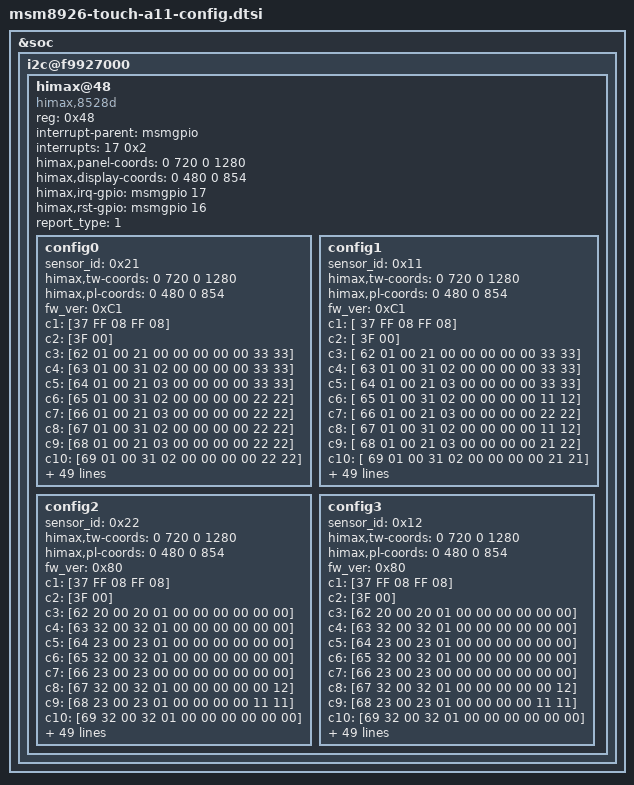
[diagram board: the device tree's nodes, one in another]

/* Copyright (c) 2013, The Linux Foundation. All rights reserved.
 *
 * This program is free software; you can redistribute it and/or modify
 * it under the terms of the GNU General Public License version 2 and
 * only version 2 as published by the Free Software Foundation.
 *
 * This program is distributed in the hope that it will be useful,
 * but WITHOUT ANY WARRANTY; without even the implied warranty of
 * MERCHANTABILITY or FITNESS FOR A PARTICULAR PURPOSE.  See the
 * GNU General Public License for more details.
 */

&soc {
	i2c@f9927000 { /* BLSP1 QUP5 */
		himax@48 {
		compatible               	= "himax,8528d";
		reg                      		= <0x48>;
		interrupt-parent         	= <&msmgpio>;
		interrupts               	= <17 0x2>;
		himax,panel-coords   	= <0 720 0 1280>;
		himax,display-coords 	= <0 480 0 854>;
		himax,irq-gpio       	= <&msmgpio 17 0x00>;
		himax,rst-gpio       	= <&msmgpio 16 0x00>;
		report_type              	= <1>;

	config0 {	//A3 Henghao edge lamination 2nd
			sensor_id   	= <0x21>;
			himax,tw-coords   	= <0 720 0 1280>;
			himax,pl-coords 	= <0 480 0 854>;
			fw_ver     	= <0xC1>;
			c1 =[37 FF 08 FF 08];
			c2 =[3F 00];
			c3 =[62 01 00 21 00 00 00 00 00 33 33];
			c4 =[63 01 00 31 02 00 00 00 00 33 33];
			c5 =[64 01 00 21 03 00 00 00 00 33 33];
			c6 =[65 01 00 31 02 00 00 00 00 22 22];
			c7 =[66 01 00 21 03 00 00 00 00 22 22];
			c8 =[67 01 00 31 02 00 00 00 00 22 22];
			c9 =[68 01 00 21 03 00 00 00 00 22 22];
			c10 =[69 01 00 31 02 00 00 00 00 22 22];
			c11 =[6A 01 00 21 00 00 00 00 00 02 00];
			c12 =[6B 01 00 01 02 00 00 00 00 00 00];
			c13 =[6C 01 00 21 00 00 00 00 00 00 00];
			c14 =[6D 01 00 01 02 00 00 00 00 00 00];
			c15 =[6E 00 00 20 00 00 00 00 00 00 00];
			c16 =[6F 00 00 00 02 00 00 00 00 00 00];
			c17 =[70 00 00 00 00 00 00 00 00 00 00];
			c18 =[7B 03];
			c19 =[7C 00 D8 0C];
			c20 =[7F 00 04 0A 0A 04 00 00 00];
			c21 =[A4 94 62 94 86];
			c22 =[B4 06 01 02 02 02 03 0F 03 0F 03
			          0F 03 0F 08];
			c23 =[B9 01 36];
			c24 =[BA 00];
			c25 =[BB 00];
			c26 =[BC 00 00 00 00];
			c27 =[BD 04 0C];
			c28 =[C2 10 00 00 00 00 00 00 00];
			c29 =[C5 0A 1B 00 10 1A 1E 0B 1A 08 16];
			c30 =[C6 17 10 1E];
			c31 =[C9 00 00 00 26 24 22 20 1C 1A 18
			          16 14 12 10 25 23 21 1D 1B 19
			          17 15 13 11 00 00 00 00 00 00
			          00 00 00 00 00 00 00 00 00 00
			          00 00 00 00 00 00 00 00 00 00
			          00 00 00 00 00 00 00 00 00 00
			          00 00 00 00];
			c32 =[CB 01 F5 FF FF 01 00 05 00 5F 00
			          00 00];
			c33 =[D0 06 01];
			c34 =[D3 06 01];
			c35 =[D5 29 00 00 00 00 00 00 00 00 00
			          00 00 00 00 00 00];
			c36 =[40 0D 5A
			          5F 00 F0 10 00 00
			          38 0C 0B 12 0A 0C 0A 0C 0C 0C
			          24 20 40 40 3C 00 00 00 00 05
			          10 20];
			c37 =[40 94 08 80 83 84 00
			          48 24 0F 14 83 3C 00 00
			          11 00 41 42
			          0F 3F 00 12 00 00
			          10 02 3C 64 00 00];
			c38 =[40 18 3F 3F 04 14 00 00 00
			          04 06 24 06 06 00 00 00];
			c39 =[40 30 58 05 00 00 D8 0C 00 00 02
			          03 80 00 00 00 00
			          10 02 80 00 00 00 00 0C];
			c40 =[40 00 00 00 00 00 00 00 00
			          A0 82 2D 01
			          0C 15 A0 13
			          00 00 02 D0 05 01];
			c41 =[40 03 E2 08 01 47 3F 08 00 61 01
			          6A 41 28 0C
			          05 EF 0C 3D 4C 95 00 00 E4 03
			          56 45 8F 00];
			c42 =[40 00 00 00 00 00 00 00 00];
			c43_1 =[40 04 20 FF FF 08 1F 12 FF 03 1E
			             11 FF 09 1D 10 FF 02 1C 0F FF
			             07 1B 0E FF 05 1A 0D FF 06 19
			             0C];
			c43_2 =[40 FF 0A 18 FF FF 01 17 FF FF
			             0B 16 FF FF 00 15 FF FF FF 14
			             FF FF FF 13 FF FF FF FF FF FF];
			c44_1 =[40 A3 00 20 00 13 1E 32 00 00 00
			             00 00 00 00 00 00 00 00 00 00
			             00 00 00 00 00 00 00 00 00 00
			             56];
			c44_2 =[40 02 12 02 00 04];
			c45   =[40 00 00];
			};

	config1 {	//Henghao edge lamination, with connecting line
			sensor_id   	= <0x11>;
			himax,tw-coords   	= <0 720 0 1280>;
			himax,pl-coords 	= <0 480 0 854>;
			fw_ver     	= <0xC1>;

			c1 =  [ 37 FF 08 FF 08];
			c2 =  [ 3F 00];
			c3 =  [ 62 01 00 21 00 00 00 00 00 33 33];
			c4 =  [ 63 01 00 31 02 00 00 00 00 33 33];
			c5 =  [ 64 01 00 21 03 00 00 00 00 33 33];
			c6 =  [ 65 01 00 31 02 00 00 00 00 11 12];
			c7 =  [ 66 01 00 21 03 00 00 00 00 22 22];
			c8 =  [ 67 01 00 31 02 00 00 00 00 11 12];
			c9 =  [ 68 01 00 21 03 00 00 00 00 21 22];
			c10 = [ 69 01 00 31 02 00 00 00 00 21 21];
			c11 = [ 6A 01 00 21 00 00 00 00 00 01 00];
			c12 = [ 6B 01 00 01 02 00 00 00 00 00 00];
			c13 = [ 6C 01 00 21 00 00 00 00 00 00 00];
			c14 = [ 6D 01 00 01 02 00 00 00 00 00 00];
			c15 = [ 6E 00 00 20 00 00 00 00 00 00 00];
			c16 = [ 6F 00 00 00 02 00 00 00 00 00 00];
			c17 = [ 70 00 00 00 00 00 00 00 00 00 00];
			c18 = [ 7B 03];
			c19 = [ 7C 00 D8 0C];
			c20 = [ 7F 00 04 0A 0A 04 00 00 00];
			c21 = [ A4 94 62 94 86];
			c22 = [ B4 06 01 02 02 02 03 0F 03 0F 03
			               0F 03 0F 08];
			c23 = [ B9 01 36];
			c24 = [ BA 00];
			c25 = [ BB 00];
			c26 = [ BC 00 00 00 00];
			c27 = [ BD 04 0C];
			c28 = [ C2 10 00 00 00 00 00 00 00];
			c29 = [ C5 0A 1F 00 10 1A 1E 0B 1F 08 16];
			c30 = [ C6 17 10 1E];
			c31 = [ C9 00 00 00 26 24 22 20 1C 1A 18
			               16 14 12 10 25 23 21 1D 1B 19
			               17 15 13 11 00 00 00 00 00 00
			               00 00 00 00 00 00 00 00 00 00
			               00 00 00 00 00 00 00 00 00 00
			               00 00 00 00 00 00 00 00 00 00
			               00 00 00 00];
			c32 = [ CB 01 F5 FF FF 01 00 05 00 5F 00
			               00 00];
			c33 = [ D0 06 01];
			c34 = [ D3 06 01];
			c35 = [ D5 29 00 00 00 00 00 00 00 00 00
			               00 00 00 00 00 00];
			c36 = [ 40 0D 5A
			               5F 00 F0 10 00 00
			               38 0C 0B 12 0A 0C 0A 0C 0C 0C
			               24 20 40 40 3C 00 00 00 00 05
			               10 20];
			c37 = [ 40 94 08 80 83 84 00
			               48 24 0F 14 83 3C 00 00
			               11 00 41 42
			               0F 3F 00 12 00 00
			               10 02 3C 64 00 00];
			c38 = [ 40 18 3F 3F 04 14 00 00 00
			               04 06 24 06 06 00 00 00];
			c39 = [ 40 30 58 05 00 00 D8 0C 00 00 02
			               03 80 00 00 00 00
			               10 02 80 00 00 00 00 0C];
			c40 = [ 40 00 00 00 00 00 00 00 00
			               A0 82 2D 01
			               0C 15 A0 13
			               00 00 02 D0 05 01];
			c41 = [ 40 03 E2 08 01 47 3F 08 00 61 01
			               6A 41 28 0C
			               05 EF 0C 3D 4C 95 00 00 E4 03
			               56 45 8F 00];
			c42 = [ 40 00 00 00 00 00 00 00 00];

			c43_1 = [ 40 04 20 FF FF 08 1F 12 FF 03 1E
			                 11 FF 09 1D 10 FF 02 1C 0F FF
			                 07 1B 0E FF 05 1A 0D FF 06 19
			                 0C];
			c43_2 = [ 40 FF 0A 18 FF FF 01 17 FF FF
			                 0B 16 FF FF 00 15 FF FF FF 14
			                 FF FF FF 13 FF FF FF FF FF FF];
			c44_1 = [ 40 A3 00 20 00 13 1E 32 00 00 00
			                 00 00 00 00 00 00 00 00 00 00
			                 00 00 00 00 00 00 00 00 00 00
			                 56];
			c44_2 = [ 40       02 12 02 00 04];
			c45   = [ 40 00 00];
			};

	config2 {//YFO one layer TW for A11#CHL&AIO, version begins from 0x80
			sensor_id   	= <0x22>;
			himax,tw-coords   	= <0 720 0 1280>;
			himax,pl-coords 	= <0 480 0 854>;
			fw_ver     	= <0x80>;
			c1 =[37 FF 08 FF 08];
			c2 =[3F 00];
			c3 =[62 20 00 20 01 00 00 00 00 00 00];
			c4 =[63 32 00 32 01 00 00 00 00 00 00];
			c5 =[64 23 00 23 01 00 00 00 00 00 00];
			c6 =[65 32 00 32 01 00 00 00 00 00 00];
			c7 =[66 23 00 23 00 00 00 00 00 00 00];
			c8 =[67 32 00 32 01 00 00 00 00 00 12];
			c9 =[68 23 00 23 01 00 00 00 00 11 11];
			c10 =[69 32 00 32 01 00 00 00 00 00 00];
			c11 =[6A 23 00 23 00 00 00 00 00 00 00];
			c12 =[6B 02 00 02 00 00 00 00 00 00 00];
			c13 =[6C 20 00 20 00 00 00 00 00 00 00];
			c14 =[6D 02 00 02 00 00 00 00 00 00 00];
			c15 =[6E 20 00 20 00 00 00 00 00 00 00];
			c16 =[6F 02 00 02 00 00 00 00 00 00 00];
			c17 =[70 00 00 00 00 00 00 00 00 00 00];
			c18 =[7B 03];
			c19 =[7C 00 D8 0C];
			c20 =[7F 00 04 0A 0A 04 00 00 00];
			c21 =[A4 94 62 94 86];
			c22 =[B4 07 01 01 01 01 03 0F 04 07 04
			               07 04 07 00];
			c23 =[B9 01 36];
			c24 =[BA 00];
			c25 =[BB 00];
			c26 =[BC 00 00 08 00];
			c27 =[BD 05 0C];
			c28 =[C2 10 00 00 00 00 00 00 00];
			c29 =[C5 05 1D 00 12 1B 1E 0B 1D 08 16];
			c30 =[C6 16 12 1A];
			c31 =[C9 00 00 00 04 04 02 02 06 06 08
			               08 03 03 01 01 07 07 00 00 00
			               00 00 00 00 00 00 00 00 00 00
			               00 00 00 00 00 00 00 00 00 00
			               00 00 00 00 00 00 00 00 00 00
			               00 00 00 00 00 00 00 00 00 00
			               00 00 00 00];
			c32 =[CB 01 F5 FF FF 01 00 05 00 9F 00
			               00 00];
			c33 =[D0 06 01];
			c34 =[D3 06 01];
			c35 =[D5 25 00 00 00 00 00 00 00 00 00
			               00 00 00 00 00 00];
			c36 =[40 33 5A
			               5F 04 7C 03 00 00
			               64 0A 0A 0C 08 0C 0A 0A 0A 0A
			               30 20 30 38 00 38 0B 0C 01 20
			               20 20];
			c37 =[40 53 08 61 62 F3 00
			               38 1C 0F 0F 83 3C 00 00
			               11 00 00 00
			               0F 0F 00 12 02 00
			               10 01 3C 64 00 00];
			c38 =[40 FF 8F 8F 05 19 05 12 70
			               04 03 12 07 07 00 00 00];
			c39 =[40 28 0F 05 00 00 D8 0C 00 00 02
			               03 80 00 00 00 00
			               10 02 80 00 00 00 00 0C];
			c40 =[40 10 07 20 20 13 0D 05 00
			               AA 8C 20 4C
			               16 07 50 23
			               00 00 02 D0 05 01];
			c41 =[40 06 1D 0B 77 4F DB 08 08 D9 12
			               40 82 E9 0C
			               08 D8 10 96 55 B9 00 0B ED 18
			               99 8A E9 00];
			c42 =[40 00 00 00 00 00 00 00 00];

			c43_1 =[40 19 15 FF FF 18 14 07 FF 17 13
			                 06 FF 16 12 05 FF FF 11 04 FF
			                 1A 10 03 FF 1B 0F 02 FF 1C 0E
			                 01];
			c43_2 =[40 FF FF 0D 00 FF FF 0C FF FF
			                 FF 0B FF FF FF 0A FF FF FF 09
			                 FF FF FF 08 FF FF FF FF FF FF];
			c44_1 =[40 22 20 06 04 01 01 0C 50 16 12
			                 19 16 12 19 1F 10 1B 1D 12 1E
			                 00 00 00 00 00 00 00 00 00 0F
			                 00];
			c44_2 =[40 00 00 00 00 05];
			c45   =[40 00 00];
			};

	config3 {//YFO one layer TW for A11#CHL&AIO, version begins from 0x80, sensor_id 0x12 for truly
			sensor_id   	= <0x12>;
			himax,tw-coords   	= <0 720 0 1280>;
			himax,pl-coords 	= <0 480 0 854>;
			fw_ver     	= <0x80>;
			c1 =[37 FF 08 FF 08];
			c2 =[3F 00];
			c3 =[62 20 00 20 01 00 00 00 00 00 00];
			c4 =[63 32 00 32 01 00 00 00 00 00 00];
			c5 =[64 23 00 23 01 00 00 00 00 00 00];
			c6 =[65 32 00 32 01 00 00 00 00 00 00];
			c7 =[66 23 00 23 00 00 00 00 00 00 00];
			c8 =[67 32 00 32 01 00 00 00 00 00 12];
			c9 =[68 23 00 23 01 00 00 00 00 11 11];
			c10 =[69 32 00 32 01 00 00 00 00 00 00];
			c11 =[6A 23 00 23 00 00 00 00 00 00 00];
			c12 =[6B 02 00 02 00 00 00 00 00 00 00];
			c13 =[6C 20 00 20 00 00 00 00 00 00 00];
			c14 =[6D 02 00 02 00 00 00 00 00 00 00];
			c15 =[6E 20 00 20 00 00 00 00 00 00 00];
			c16 =[6F 02 00 02 00 00 00 00 00 00 00];
			c17 =[70 00 00 00 00 00 00 00 00 00 00];
			c18 =[7B 03];
			c19 =[7C 00 D8 0C];
			c20 =[7F 00 04 0A 0A 04 00 00 00];
			c21 =[A4 94 62 94 86];
			c22 =[B4 07 01 01 01 01 03 0F 04 07 04
			               07 04 07 00];
			c23 =[B9 01 36];
			c24 =[BA 00];
			c25 =[BB 00];
			c26 =[BC 00 00 08 00];
			c27 =[BD 05 0C];
			c28 =[C2 10 00 00 00 00 00 00 00];
			c29 =[C5 05 1D 00 12 1B 1E 0B 1D 08 16];
			c30 =[C6 16 12 1A];
			c31 =[C9 00 00 00 04 04 02 02 06 06 08
			               08 03 03 01 01 07 07 00 00 00
			               00 00 00 00 00 00 00 00 00 00
			               00 00 00 00 00 00 00 00 00 00
			               00 00 00 00 00 00 00 00 00 00
			               00 00 00 00 00 00 00 00 00 00
			               00 00 00 00];
			c32 =[CB 01 F5 FF FF 01 00 05 00 9F 00
			               00 00];
			c33 =[D0 06 01];
			c34 =[D3 06 01];
			c35 =[D5 25 00 00 00 00 00 00 00 00 00
			               00 00 00 00 00 00];
			c36 =[40 33 5A
			               5F 04 7C 03 00 00
			               64 0A 0A 0C 08 0C 0A 0A 0A 0A
			               30 20 30 38 00 38 0B 0C 01 20
			               20 20];
			c37 =[40 53 08 61 62 F3 00
			               38 1C 0F 0F 83 3C 00 00
			               11 00 00 00
			               0F 0F 00 12 02 00
			               10 01 3C 64 00 00];
			c38 =[40 FF 8F 8F 05 19 05 12 70
			               04 03 12 07 07 00 00 00];
			c39 =[40 28 0F 05 00 00 D8 0C 00 00 02
			               03 80 00 00 00 00
			               10 02 80 00 00 00 00 0C];
			c40 =[40 10 07 20 20 13 0D 05 00
			               AA 8C 20 4C
			               16 07 50 23
			               00 00 02 D0 05 01];
			c41 =[40 06 1D 0B 77 4F DB 08 08 D9 12
			               40 82 E9 0C
			               08 D8 10 96 55 B9 00 0B ED 18
			               99 8A E9 00];
			c42 =[40 00 00 00 00 00 00 00 00];

			c43_1 =[40 19 15 FF FF 18 14 07 FF 17 13
			                 06 FF 16 12 05 FF FF 11 04 FF
			                 1A 10 03 FF 1B 0F 02 FF 1C 0E
			                 01];
			c43_2 =[40 FF FF 0D 00 FF FF 0C FF FF
			                 FF 0B FF FF FF 0A FF FF FF 09
			                 FF FF FF 08 FF FF FF FF FF FF];
			c44_1 =[40 22 20 06 04 01 01 0C 50 16 12
			                 19 16 12 19 1F 10 1B 1D 12 1E
			                 00 00 00 00 00 00 00 00 00 0F
			                 00];
			c44_2 =[40 00 00 00 00 05];
			c45   =[40 00 00];
		};
		};
	};
};
